# MKL28Z7 register map
Vendor: Freescale Semiconductor, Inc.; Series: Kinetis_L; File version: 1.6
CPU: CM0PLUS r0p0, little endian, no MPU, no FPU, VTOR, 2 interrupt priority bits
Registers are 32-bit, read-write, reset 0x0 unless marked. A register's access mark holds for its fields unless they carry their own. Offsets are from the block's base; [hi:lo] are bit positions; {n}, {i} and the like mark numbered series.

## RFSYS — System register file
Base 0x4007C000; register names take the prefix RFSYS_
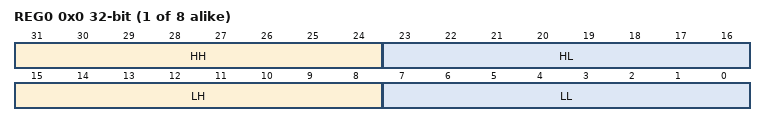
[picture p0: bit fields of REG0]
{0x0+4i} REG{i} (i=0..7) — Register file register
  [31:24] HH — High higher byte
  [23:16] HL — High lower byte
  [15:8] LH — Low higher byte
  [7:0] LL — Low lower byte

## PMC — Power Management Controller
Base 0x4007D000; register names take the prefix PMC_
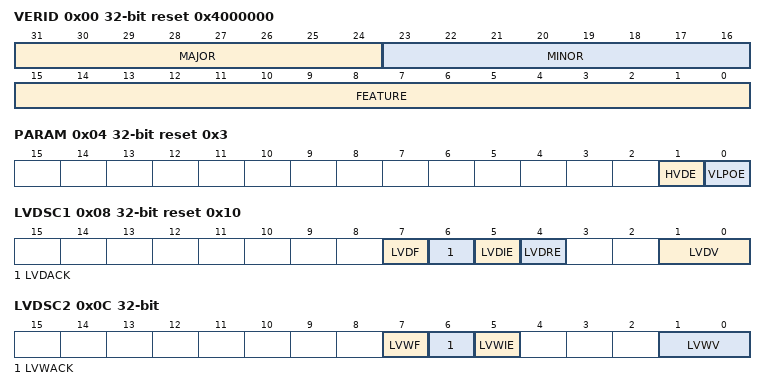
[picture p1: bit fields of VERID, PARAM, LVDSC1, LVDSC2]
0x00 VERID ro reset 0x4000000 — Version ID register
  [31:24] MAJOR — Major Version Number
  [23:16] MINOR — Minor Version Number
  [15:0] FEATURE — Feature Specification Number
    0=Standard features implemented
0x04 PARAM ro reset 0x3 — Parameter register
  [1] HVDE — HVD Enabled
  [0] VLPOE — VLPO Enable
0x08 LVDSC1 reset 0x10 — Low Voltage Detect Status And Control 1 register
  [7] LVDF ro — Low-Voltage Detect Flag
    0=Low-voltage event not detected; 1=Low-voltage event detected
  [6] LVDACK wo — Low-Voltage Detect Acknowledge
  [5] LVDIE — Low-Voltage Detect Interrupt Enable
    0=Hardware interrupt disabled (use polling); 1=Request a hardware interrupt when LVDF = 1
  [4] LVDRE — Low-Voltage Detect Reset Enable
    0=LVDF does not generate hardware resets; 1=Force an MCU reset when LVDF = 1
  [1:0] LVDV — Low-Voltage Detect Voltage Select
    0=Low trip point selected (V LVD = V LVDL ); 1=High trip point selected (V LVD = V LVDH )
0x0C LVDSC2 — Low Voltage Detect Status And Control 2 register
  [7] LVWF ro — Low-Voltage Warning Flag
    0=Low-voltage warning event not detected; 1=Low-voltage warning event detected
  [6] LVWACK wo — Low-Voltage Warning Acknowledge
  [5] LVWIE — Low-Voltage Warning Interrupt Enable
    0=Hardware interrupt disabled (use polling); 1=Request a hardware interrupt when LVWF = 1
  [1:0] LVWV — Low-Voltage Warning Voltage Select
    0=Low trip point selected (VLVW = VLVW1); 1=Mid 1 trip point selected (VLVW = VLVW2); 2=Mid 2 trip point selected (VLVW = VLVW3); 3=High trip point selected (VLVW = VLVW4)
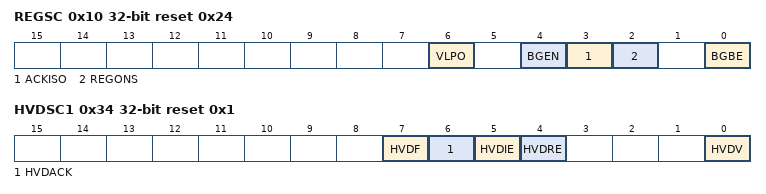
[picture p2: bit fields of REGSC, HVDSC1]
0x10 REGSC reset 0x24 — Regulator Status And Control register
  [6] VLPO — VLPx Option
    0=Operating frequencies and SCG clocking modes are restricted during VLPx modes as listed in the Power Management chapter; 1=If BGEN is also set, operating frequencies and SCG clocking modes are unrestricted during VLPx modes. Note that flash access frequency is still restricted however.
  [4] BGEN — Bandgap Enable In VLPx Operation
    0=Bandgap voltage reference is disabled in VLPx , LLS , and VLLSx modes; 1=Bandgap voltage reference is enabled in VLPx , LLS , and VLLSx modes
  [3] ACKISO — Acknowledge Isolation
    0=Peripherals and I/O pads are in normal run state; 1=Certain peripherals and I/O pads are in an isolated and latched state
  [2] REGONS ro — Regulator In Run Regulation Status
    0=Regulator is in stop regulation or in transition to/from it; 1=Regulator is in run regulation
  [0] BGBE — Bandgap Buffer Enable
    0=Bandgap buffer not enabled; 1=Bandgap buffer enabled
0x34 HVDSC1 reset 0x1 — High Voltage Detect Status And Control 1 register
  [7] HVDF ro — High-Voltage Detect Flag
    0=High-voltage event not detected; 1=High-voltage event detected
  [6] HVDACK wo — High-Voltage Detect Acknowledge
  [5] HVDIE — High-Voltage Detect Interrupt Enable
    0=Hardware interrupt disabled (use polling); 1=Request a hardware interrupt when HVDF = 1
  [4] HVDRE — High-Voltage Detect Reset Enable
    0=HVDF does not generate hardware resets; 1=Force an MCU reset when HVDF = 1
  [0] HVDV — High-Voltage Detect Voltage Select
    0=Low trip point selected (V HVD = V HVDL ); 1=High trip point selected (V HVD = V HVDH )

## SMC — System Mode Controller
Base 0x4007E000; register names take the prefix SMC_
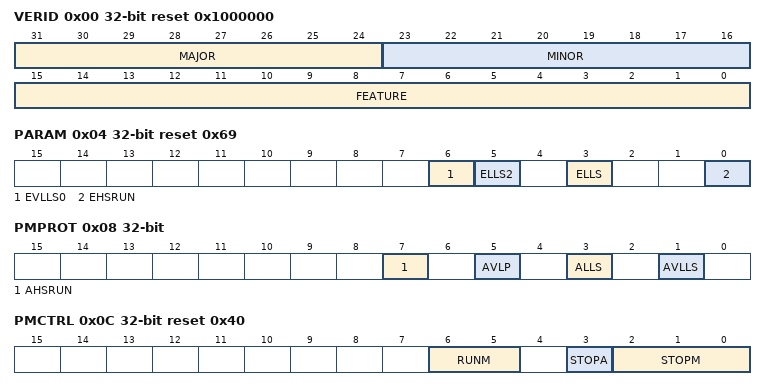
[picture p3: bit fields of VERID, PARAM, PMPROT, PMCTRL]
0x00 VERID ro reset 0x1000000 — SMC Version ID Register
  [31:24] MAJOR — Major Version Number
  [23:16] MINOR — Minor Version Number
  [15:0] FEATURE — Feature Specification Number
    0=Standard features implemented
0x04 PARAM ro reset 0x69 — SMC Parameter Register
  [all] fields
    0=The feature is not available; 1=The feature is available
  [6] EVLLS0 — Existence of VLLS0 feature
  [5] ELLS2 — Existence of LLS2 feature
  [3] ELLS — Existence of LLS feature
  [0] EHSRUN — Existence of HSRUN feature
0x08 PMPROT — Power Mode Protection register
  [7] AHSRUN — Allow High Speed Run mode
    0=HSRUN is not allowed; 1=HSRUN is allowed
  [5] AVLP — Allow Very-Low-Power Modes
    0=VLPR, VLPW, and VLPS are not allowed; 1=VLPR, VLPW, and VLPS are allowed
  [3] ALLS — Allow Low-Leakage Stop Mode
    0=Any LLSx mode is not allowed; 1=Any LLSx mode is allowed
  [1] AVLLS — Allow Very-Low-Leakage Stop Mode
    0=Any VLLSx mode is not allowed; 1=Any VLLSx mode is allowed
0x0C PMCTRL reset 0x40 — Power Mode Control register
  [6:5] RUNM — Run Mode Control
    0=Normal Run mode (RUN); 2=Very-Low-Power Run mode (VLPR); 3=High Speed Run mode (HSRUN)
  [3] STOPA ro — Stop Aborted
    0=The previous stop mode entry was successful; 1=The previous stop mode entry was aborted
  [2:0] STOPM — Stop Mode Control
    0=Normal Stop (STOP); 2=Very-Low-Power Stop (VLPS); 3=Low-Leakage Stop (LLSx); 4=Very-Low-Leakage Stop (VLLSx); 6=Reseved
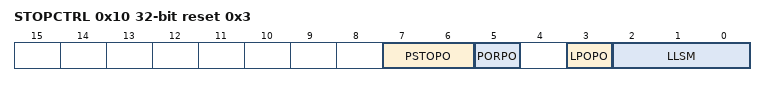
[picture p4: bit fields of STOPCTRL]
0x10 STOPCTRL reset 0x3 — Stop Control Register
  [7:6] PSTOPO — Partial Stop Option
    0=STOP - Normal Stop mode; 1=PSTOP1 - Partial Stop with both system and bus clocks disabled; 2=PSTOP2 - Partial Stop with system clock disabled and bus clock enabled
  [5] PORPO — POR Power Option
    0=POR detect circuit is enabled in VLLS0; 1=POR detect circuit is disabled in VLLS0
  [3] LPOPO — LPO Power Option
    0=LPO clock is enabled in LLS/VLLSx; 1=LPO clock is disabled in LLS/VLLSx
  [2:0] LLSM — LLS or VLLS Mode Control
    0=VLLS0 if PMCTRL[STOPM]=VLLSx, reserved if PMCTRL[STOPM]=LLSx; 1=VLLS1 if PMCTRL[STOPM]=VLLSx, reserved if PMCTRL[STOPM]=LLSx; 2=VLLS2 if PMCTRL[STOPM]=VLLSx, LLS2 if PMCTRL[STOPM]=LLSx; 3=VLLS3 if PMCTRL[STOPM]=VLLSx, LLS3 if PMCTRL[STOPM]=LLSx
0x14 PMSTAT ro reset 0x4 — Power Mode Status register
  [7:0] PMSTAT — Power Mode Status
